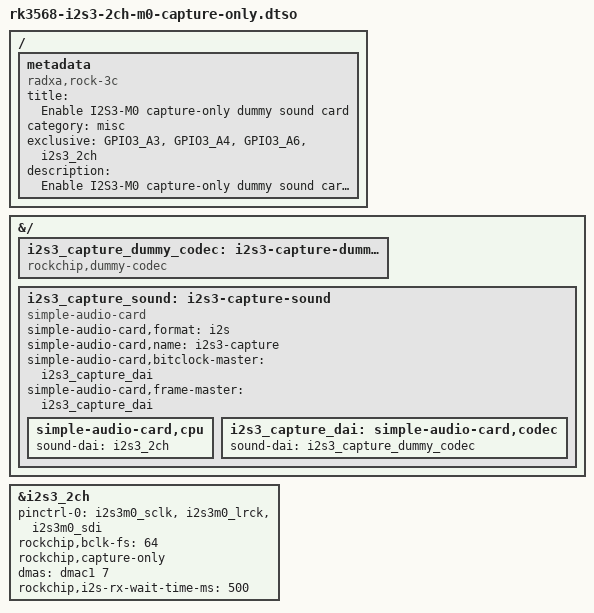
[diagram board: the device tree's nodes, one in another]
/dts-v1/;
/plugin/;

/ {
	metadata {
		title = "Enable I2S3-M0 capture-only dummy sound card";
		compatible = "radxa,rock-3c", "radxa,zero3";
		category = "misc";
		exclusive = "GPIO3_A3", "GPIO3_A4", "GPIO3_A6", "i2s3_2ch";
		description = "Enable I2S3-M0 capture-only dummy sound card in slave mode.
On Radxa ROCK 3C this is pin38 for SDI, pin35 for LRCK, pin12 for SCLK.
On Radxa ZERO 3 this is pin38 for SDI, pin35 for LRCK, pin12 for SCLK.
";
	};
};

&{/} {
	i2s3_capture_dummy_codec: i2s3-capture-dummy-codec {
		compatible = "rockchip,dummy-codec";
		#sound-dai-cells = <0>;
	};

	i2s3_capture_sound: i2s3-capture-sound {
		compatible = "simple-audio-card";
		simple-audio-card,format = "i2s";
		simple-audio-card,name = "i2s3-capture";
		simple-audio-card,bitclock-master = <&i2s3_capture_dai>;
		simple-audio-card,frame-master = <&i2s3_capture_dai>;

		simple-audio-card,cpu {
			sound-dai = <&i2s3_2ch>;
		};

		i2s3_capture_dai: simple-audio-card,codec {
			sound-dai = <&i2s3_capture_dummy_codec>;
		};
	};
};

&i2s3_2ch {
	status = "okay";
	pinctrl-names = "default";
	pinctrl-0 = <&i2s3m0_sclk &i2s3m0_lrck &i2s3m0_sdi>;
	rockchip,bclk-fs = <64>;
	rockchip,capture-only;
	dmas = <&dmac1 7>;
	dma-names = "rx";
	rockchip,i2s-rx-wait-time-ms = <500>;
};
